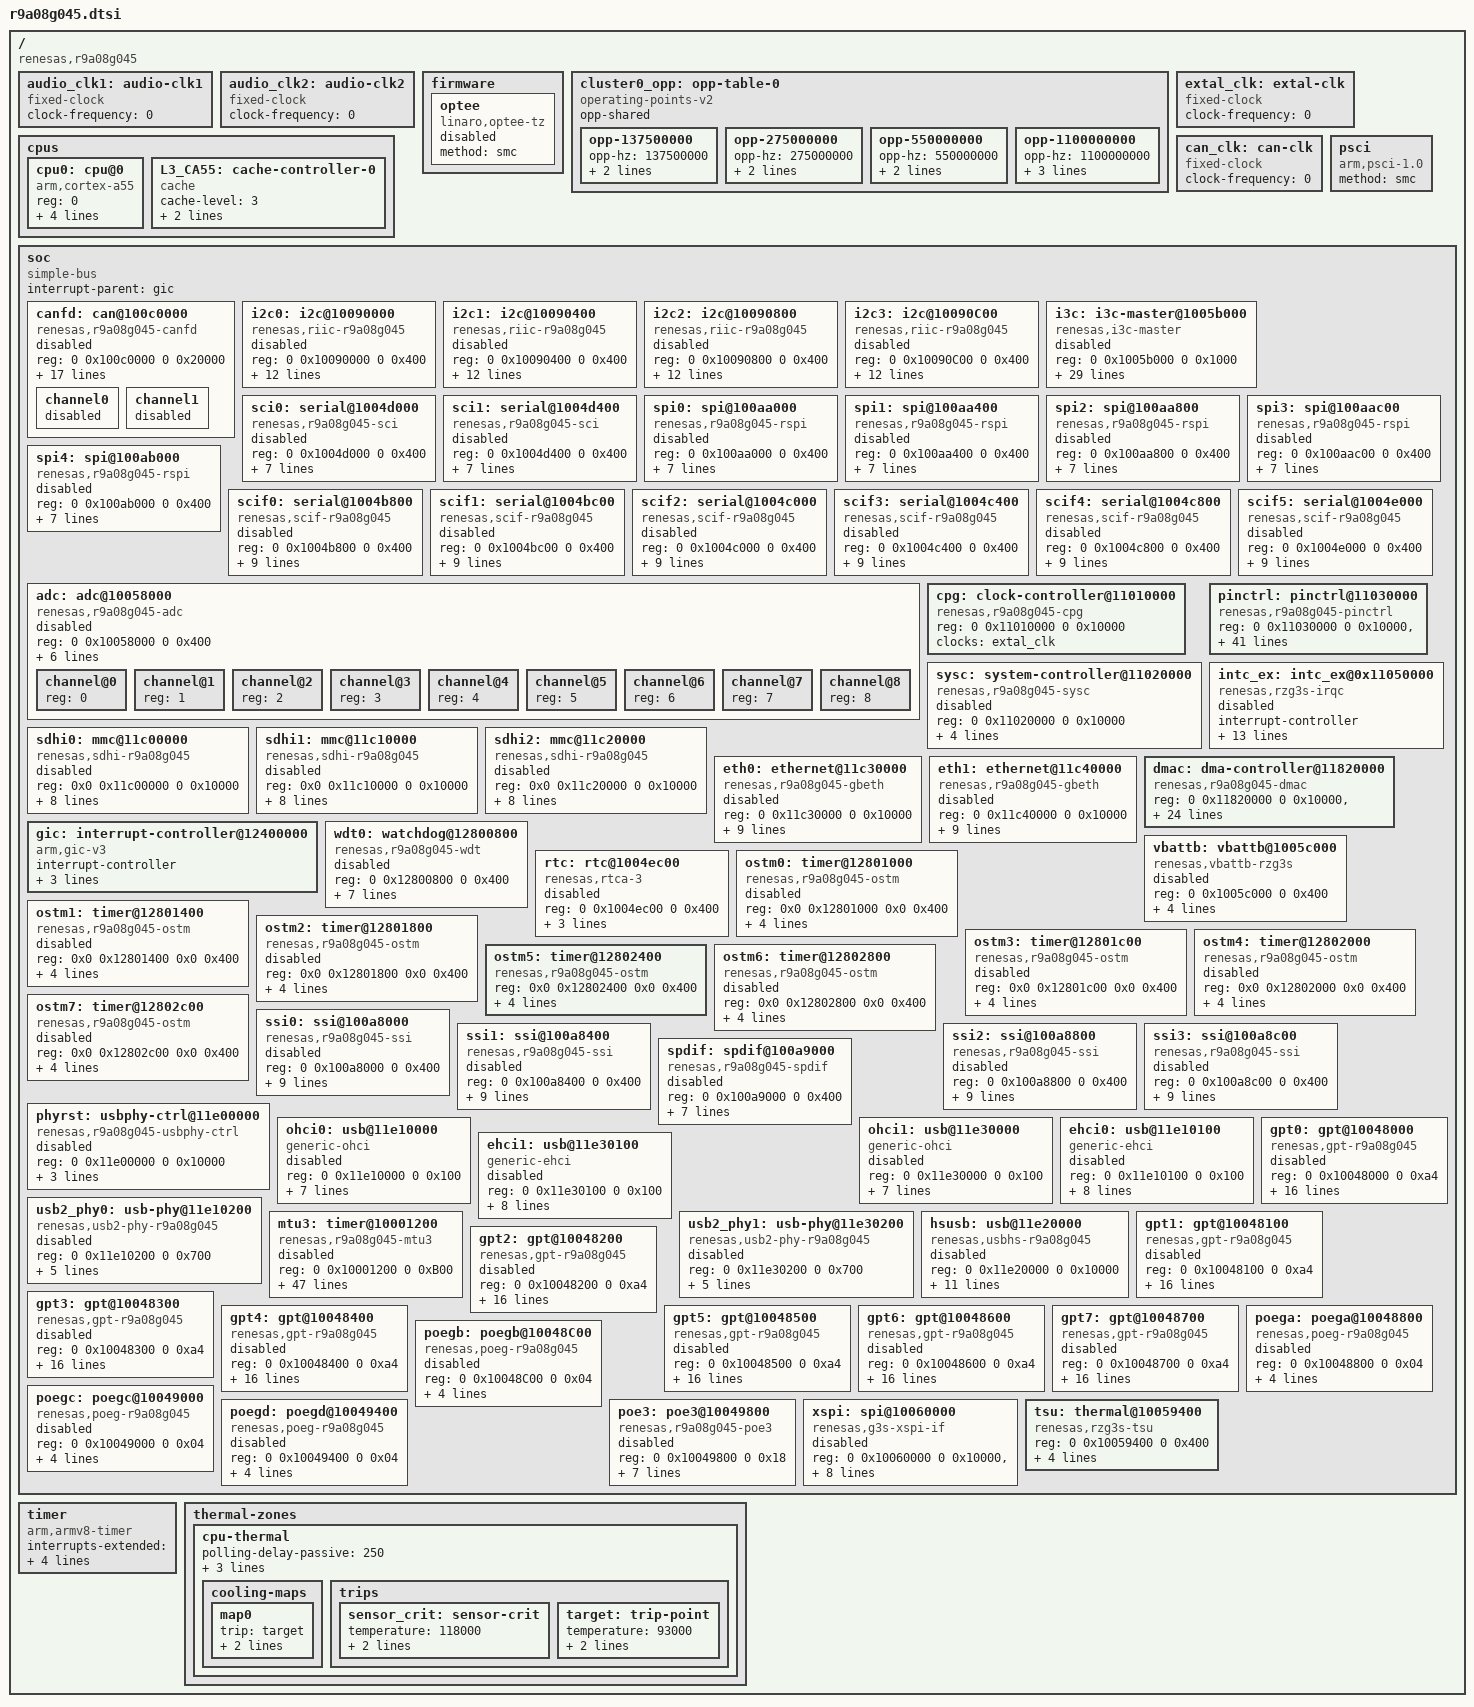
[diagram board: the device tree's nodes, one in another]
// SPDX-License-Identifier: (GPL-2.0-only OR BSD-2-Clause)
/*
 * Device Tree Source for the RZ/G3S SoC
 *
 * Copyright (C) 2023 Renesas Electronics Corp.
 */

#include <dt-bindings/interrupt-controller/arm-gic.h>
#include <dt-bindings/clock/r9a08g045-cpg.h>

/ {
	compatible = "renesas,r9a08g045";
	#address-cells = <2>;
	#size-cells = <2>;

	audio_clk1: audio-clk1 {
		compatible = "fixed-clock";
		#clock-cells = <0>;
		/* This value must be overridden by boards that provide it */
		clock-frequency = <0>;
	};

	audio_clk2: audio-clk2 {
		compatible = "fixed-clock";
		#clock-cells = <0>;
		/* This value must be overridden by boards that provide it */
		clock-frequency = <0>;
	};

	firmware {
		optee {
			compatible = "linaro,optee-tz";
			method = "smc";
			status = "disabled";
		};
	};

	cluster0_opp: opp-table-0 {
		compatible = "operating-points-v2";
		opp-shared;

		opp-137500000 {
			opp-hz = /bits/ 64 <137500000>;
			opp-microvolt = <1100000>;
			clock-latency-ns = <300000>;
		};
		opp-275000000 {
			opp-hz = /bits/ 64 <275000000>;
			opp-microvolt = <1100000>;
			clock-latency-ns = <300000>;
		};
		opp-550000000 {
			opp-hz = /bits/ 64 <550000000>;
			opp-microvolt = <1100000>;
			clock-latency-ns = <300000>;
		};
		opp-1100000000 {
			opp-hz = /bits/ 64 <1100000000>;
			opp-microvolt = <1100000>;
			clock-latency-ns = <300000>;
			opp-suspend;
		};
	};

	cpus {
		#address-cells = <1>;
		#size-cells = <0>;

		cpu0: cpu@0 {
			compatible = "arm,cortex-a55";
			reg = <0>;
			device_type = "cpu";
			#cooling-cells = <2>;
			next-level-cache = <&L3_CA55>;
			enable-method = "psci";
			clocks = <&cpg CPG_CORE R9A08G045_CLK_I>;
			operating-points-v2 = <&cluster0_opp>;
		};

		L3_CA55: cache-controller-0 {
			compatible = "cache";
			cache-level = <3>;
			cache-unified;
			cache-size = <0x40000>;
		};
	};

	extal_clk: extal-clk {
		compatible = "fixed-clock";
		#clock-cells = <0>;
		/* This value must be overridden by the board. */
		clock-frequency = <0>;
	};

	/* External CAN clock - to be overridden by boards that provide it */
	can_clk: can-clk {
		compatible = "fixed-clock";
		#clock-cells = <0>;
		 clock-frequency = <0>;
	};

	psci {
		compatible = "arm,psci-1.0", "arm,psci-0.2";
		method = "smc";
	};

	soc: soc {
		compatible = "simple-bus";
		interrupt-parent = <&gic>;
		#address-cells = <2>;
		#size-cells = <2>;
		ranges;

		canfd: can@100c0000 {
			compatible = "renesas,r9a08g045-canfd", "renesas,rzg3s-canfd";
			reg = <0 0x100c0000 0 0x20000>;
			interrupts = <GIC_SPI 373 IRQ_TYPE_LEVEL_HIGH>,
				     <GIC_SPI 374 IRQ_TYPE_LEVEL_HIGH>,
				     <GIC_SPI 375 IRQ_TYPE_LEVEL_HIGH>,
				     <GIC_SPI 376 IRQ_TYPE_LEVEL_HIGH>,
				     <GIC_SPI 377 IRQ_TYPE_LEVEL_HIGH>,
				     <GIC_SPI 378 IRQ_TYPE_LEVEL_HIGH>,
				     <GIC_SPI 379 IRQ_TYPE_LEVEL_HIGH>,
				     <GIC_SPI 380 IRQ_TYPE_LEVEL_HIGH>;
			interrupt-names = "g_err", "g_recc",
					  "ch0_rec", "ch1_rec", "ch0_err",
					  "ch1_err", "ch0_trx", "ch1_trx";
			clocks = <&cpg CPG_MOD R9A08G045_CANFD_CLK_RAM>,
				 <&cpg CPG_MOD R9A08G045_CANFD_PCLK>,
				 <&cpg CPG_CORE R9A08G045_CLK_CANFD>,
				 <&can_clk>;
			clock-names = "ram_clk", "fck", "canfd", "can_clk";
			assigned-clocks = <&cpg CPG_MOD R9A08G045_CANFD_PCLK>;
			assigned-clock-rates = <80000000>;
			resets = <&cpg R9A08G045_CANFD_RSTP_N>,
				 <&cpg R9A08G045_CANFD_RSTC_N>;
			reset-names = "rstp_n", "rstc_n";
			power-domains = <&cpg>;
			status = "disabled";

			channel0 {
				 status = "disabled";
			};
			channel1 {
				status = "disabled";
			};
		};

		i2c0: i2c@10090000 {
			#address-cells = <1>;
			#size-cells = <0>;
			compatible = "renesas,riic-r9a08g045";
			reg = <0 0x10090000 0 0x400>;
			interrupts = <GIC_SPI 257 IRQ_TYPE_LEVEL_HIGH>,
				     <GIC_SPI 263 IRQ_TYPE_EDGE_RISING>,
				     <GIC_SPI 264 IRQ_TYPE_EDGE_RISING>,
				     <GIC_SPI 259 IRQ_TYPE_LEVEL_HIGH>,
				     <GIC_SPI 260 IRQ_TYPE_LEVEL_HIGH>,
				     <GIC_SPI 258 IRQ_TYPE_LEVEL_HIGH>,
				     <GIC_SPI 261 IRQ_TYPE_LEVEL_HIGH>,
				     <GIC_SPI 262 IRQ_TYPE_LEVEL_HIGH>;
			interrupt-names = "tei", "ri", "ti", "spi", "sti",
					  "naki", "ali", "tmoi";
			clocks = <&cpg CPG_MOD R9A08G045_I2C0_PCLK>;
			clock-frequency = <100000>;
			resets = <&cpg R9A08G045_I2C0_MRST>;
			power-domains = <&cpg>;
			status = "disabled";
		};

		i2c1: i2c@10090400 {
			#address-cells = <1>;
			#size-cells = <0>;
			compatible = "renesas,riic-r9a08g045";
			reg = <0 0x10090400 0 0x400>;
			interrupts = <GIC_SPI 265 IRQ_TYPE_LEVEL_HIGH>,
				     <GIC_SPI 271 IRQ_TYPE_EDGE_RISING>,
				     <GIC_SPI 272 IRQ_TYPE_EDGE_RISING>,
				     <GIC_SPI 267 IRQ_TYPE_LEVEL_HIGH>,
				     <GIC_SPI 268 IRQ_TYPE_LEVEL_HIGH>,
				     <GIC_SPI 266 IRQ_TYPE_LEVEL_HIGH>,
				     <GIC_SPI 269 IRQ_TYPE_LEVEL_HIGH>,
				     <GIC_SPI 270 IRQ_TYPE_LEVEL_HIGH>;
			interrupt-names = "tei", "ri", "ti", "spi", "sti",
					  "naki", "ali", "tmoi";
			clocks = <&cpg CPG_MOD R9A08G045_I2C1_PCLK>;
			clock-frequency = <100000>;
			resets = <&cpg R9A08G045_I2C1_MRST>;
			power-domains = <&cpg>;
			status = "disabled";
		};

		i2c2: i2c@10090800 {
			#address-cells = <1>;
			#size-cells = <0>;
			compatible = "renesas,riic-r9a08g045";
			reg = <0 0x10090800 0 0x400>;
			interrupts = <GIC_SPI 273 IRQ_TYPE_LEVEL_HIGH>,
				     <GIC_SPI 279 IRQ_TYPE_EDGE_RISING>,
				     <GIC_SPI 280 IRQ_TYPE_EDGE_RISING>,
				     <GIC_SPI 275 IRQ_TYPE_LEVEL_HIGH>,
				     <GIC_SPI 276 IRQ_TYPE_LEVEL_HIGH>,
				     <GIC_SPI 274 IRQ_TYPE_LEVEL_HIGH>,
				     <GIC_SPI 277 IRQ_TYPE_LEVEL_HIGH>,
				     <GIC_SPI 278 IRQ_TYPE_LEVEL_HIGH>;
			interrupt-names = "tei", "ri", "ti", "spi", "sti",
					  "naki", "ali", "tmoi";
			clocks = <&cpg CPG_MOD R9A08G045_I2C2_PCLK>;
			clock-frequency = <100000>;
			resets = <&cpg R9A08G045_I2C2_MRST>;
			power-domains = <&cpg>;
			status = "disabled";
		};

		i2c3: i2c@10090C00 {
			#address-cells = <1>;
			#size-cells = <0>;
			compatible = "renesas,riic-r9a08g045";
			reg = <0 0x10090C00 0 0x400>;
			interrupts = <GIC_SPI 281 IRQ_TYPE_LEVEL_HIGH>,
				     <GIC_SPI 287 IRQ_TYPE_EDGE_RISING>,
				     <GIC_SPI 288 IRQ_TYPE_EDGE_RISING>,
				     <GIC_SPI 283 IRQ_TYPE_LEVEL_HIGH>,
				     <GIC_SPI 284 IRQ_TYPE_LEVEL_HIGH>,
				     <GIC_SPI 282 IRQ_TYPE_LEVEL_HIGH>,
				     <GIC_SPI 285 IRQ_TYPE_LEVEL_HIGH>,
				     <GIC_SPI 286 IRQ_TYPE_LEVEL_HIGH>;
			interrupt-names = "tei", "ri", "ti", "spi", "sti",
					  "naki", "ali", "tmoi";
			clocks = <&cpg CPG_MOD R9A08G045_I2C3_PCLK>;
			clock-frequency = <100000>;
			resets = <&cpg R9A08G045_I2C3_MRST>;
			power-domains = <&cpg>;
			status = "disabled";
		};

		i3c: i3c-master@1005b000 {
			compatible = "renesas,i3c-master";
			reg = <0 0x1005b000 0 0x1000>;
			clocks = <&cpg CPG_MOD R9A08G045_I3C_PCLK>,
				 <&cpg CPG_MOD R9A08G045_I3C_TCLK>;
			clock-names = "pclk", "tclk";
			interrupts = <GIC_SPI 289 IRQ_TYPE_LEVEL_HIGH>,
				     <GIC_SPI 290 IRQ_TYPE_LEVEL_HIGH>,
				     <GIC_SPI 291 IRQ_TYPE_LEVEL_HIGH>,
				     <GIC_SPI 292 IRQ_TYPE_LEVEL_HIGH>,
				     <GIC_SPI 293 IRQ_TYPE_LEVEL_HIGH>,
				     <GIC_SPI 294 IRQ_TYPE_EDGE_RISING>,
				     <GIC_SPI 295 IRQ_TYPE_EDGE_RISING>,
				     <GIC_SPI 296 IRQ_TYPE_EDGE_RISING>,
				     <GIC_SPI 297 IRQ_TYPE_EDGE_RISING>,
				     <GIC_SPI 298 IRQ_TYPE_EDGE_RISING>,
				     <GIC_SPI 299 IRQ_TYPE_EDGE_RISING>,
				     <GIC_SPI 300 IRQ_TYPE_EDGE_RISING>,
				     <GIC_SPI 301 IRQ_TYPE_EDGE_RISING>,
				     <GIC_SPI 302 IRQ_TYPE_EDGE_RISING>,
				     <GIC_SPI 303 IRQ_TYPE_EDGE_RISING>,
				     <GIC_SPI 304 IRQ_TYPE_LEVEL_HIGH>,
				     <GIC_SPI 305 IRQ_TYPE_LEVEL_HIGH>,
				     <GIC_SPI 306 IRQ_TYPE_LEVEL_HIGH>,
				     <GIC_SPI 307 IRQ_TYPE_LEVEL_HIGH>,
				     <GIC_SPI 308 IRQ_TYPE_LEVEL_HIGH>,
				     <GIC_SPI 309 IRQ_TYPE_LEVEL_HIGH>,
				     <GIC_SPI 310 IRQ_TYPE_LEVEL_HIGH>,
				     <GIC_SPI 311 IRQ_TYPE_LEVEL_HIGH>;
			interrupt-names = "ierr", "terr", "hterr", "habort", "abort",
					  "resp", "cmd", "ibi", "rx", "tx", "rcv",
					  "hresp", "hcmd", "hrx", "htx", "st", "sp",
					  "exit", "tend", "nack", "al", "tmo", "wu";
			resets = <&cpg R9A08G045_I3C_TRESETN>,
				 <&cpg R9A08G045_I3C_PRESETN>;
			reset-names = "tresetn", "presetn";
			#address-cells = <3>;
			#size-cells = <0>;
			i2c-scl-hz = <1000000>;
			i3c-scl-hz = <12500000>;
			status = "disabled";
		};

		sci0: serial@1004d000 {
			compatible = "renesas,r9a08g045-sci", "renesas,sci";
			reg = <0 0x1004d000 0 0x400>;
			interrupts = <GIC_SPI 350 IRQ_TYPE_LEVEL_HIGH>,
				     <GIC_SPI 351 IRQ_TYPE_EDGE_RISING>,
				     <GIC_SPI 352 IRQ_TYPE_EDGE_RISING>,
				     <GIC_SPI 353 IRQ_TYPE_LEVEL_HIGH>;
			interrupt-names = "eri", "rxi", "txi", "tei";
			clocks = <&cpg CPG_MOD R9A08G045_SCI0_CLKP>;
			clock-names = "fck";
			power-domains = <&cpg>;
			resets = <&cpg R9A08G045_SCI0_RST>;
			status = "disabled";
		};

		sci1: serial@1004d400 {
			compatible = "renesas,r9a08g045-sci", "renesas,sci";
			reg = <0 0x1004d400 0 0x400>;
			interrupts = <GIC_SPI 354 IRQ_TYPE_LEVEL_HIGH>,
				     <GIC_SPI 355 IRQ_TYPE_EDGE_RISING>,
				     <GIC_SPI 356 IRQ_TYPE_EDGE_RISING>,
				     <GIC_SPI 357 IRQ_TYPE_LEVEL_HIGH>;
			interrupt-names = "eri", "rxi", "txi", "tei";
			clocks = <&cpg CPG_MOD R9A08G045_SCI1_CLKP>;
			clock-names = "fck";
			power-domains = <&cpg>;
			resets = <&cpg R9A08G045_SCI1_RST>;
			status = "disabled";
		};

		spi0: spi@100aa000 {
			compatible = "renesas,r9a08g045-rspi", "renesas,rspi-rz";
			reg = <0 0x100aa000 0 0x400>;
			interrupts = <GIC_SPI 358 IRQ_TYPE_LEVEL_HIGH>,
				     <GIC_SPI 359 IRQ_TYPE_LEVEL_HIGH>,
				     <GIC_SPI 360 IRQ_TYPE_LEVEL_HIGH>;
			interrupt-names = "error", "rx", "tx";
			clocks = <&cpg CPG_MOD R9A08G045_RSPI0_CLKB>;
			resets = <&cpg R9A08G045_RSPI0_RST>;
			power-domains = <&cpg>;
			num-cs = <1>;
			#address-cells = <1>;
			#size-cells = <0>;
			status = "disabled";
		};

		spi1: spi@100aa400 {
			compatible = "renesas,r9a08g045-rspi", "renesas,rspi-rz";
			reg = <0 0x100aa400 0 0x400>;
			interrupts = <GIC_SPI 361 IRQ_TYPE_LEVEL_HIGH>,
				     <GIC_SPI 362 IRQ_TYPE_LEVEL_HIGH>,
				     <GIC_SPI 363 IRQ_TYPE_LEVEL_HIGH>;
			interrupt-names = "error", "rx", "tx";
			clocks = <&cpg CPG_MOD R9A08G045_RSPI1_CLKB>;
			resets = <&cpg R9A08G045_RSPI1_RST>;
			power-domains = <&cpg>;
			num-cs = <1>;
			#address-cells = <1>;
			#size-cells = <0>;
			status = "disabled";
		};

		spi2: spi@100aa800 {
			compatible = "renesas,r9a08g045-rspi", "renesas,rspi-rz";
			reg = <0 0x100aa800 0 0x400>;
			interrupts = <GIC_SPI 364 IRQ_TYPE_LEVEL_HIGH>,
				     <GIC_SPI 365 IRQ_TYPE_LEVEL_HIGH>,
				     <GIC_SPI 366 IRQ_TYPE_LEVEL_HIGH>;
			interrupt-names = "error", "rx", "tx";
			clocks = <&cpg CPG_MOD R9A08G045_RSPI2_CLKB>;
			resets = <&cpg R9A08G045_RSPI2_RST>;
			power-domains = <&cpg>;
			num-cs = <1>;
			#address-cells = <1>;
			#size-cells = <0>;
			status = "disabled";
		};

		spi3: spi@100aac00 {
			compatible = "renesas,r9a08g045-rspi", "renesas,rspi-rz";
			reg = <0 0x100aac00 0 0x400>;
			interrupts = <GIC_SPI 367 IRQ_TYPE_LEVEL_HIGH>,
				     <GIC_SPI 368 IRQ_TYPE_LEVEL_HIGH>,
				     <GIC_SPI 369 IRQ_TYPE_LEVEL_HIGH>;
			interrupt-names = "error", "rx", "tx";
			clocks = <&cpg CPG_MOD R9A08G045_RSPI3_CLKB>;
			resets = <&cpg R9A08G045_RSPI3_RST>;
			power-domains = <&cpg>;
			num-cs = <1>;
			#address-cells = <1>;
			#size-cells = <0>;
			status = "disabled";
		};

		spi4: spi@100ab000 {
			compatible = "renesas,r9a08g045-rspi", "renesas,rspi-rz";
			reg = <0 0x100ab000 0 0x400>;
			interrupts = <GIC_SPI 370 IRQ_TYPE_LEVEL_HIGH>,
				     <GIC_SPI 371 IRQ_TYPE_LEVEL_HIGH>,
				     <GIC_SPI 372 IRQ_TYPE_LEVEL_HIGH>;
			interrupt-names = "error", "rx", "tx";
			clocks = <&cpg CPG_MOD R9A08G045_RSPI4_CLKB>;
			resets = <&cpg R9A08G045_RSPI4_RST>;
			power-domains = <&cpg>;
			num-cs = <1>;
			#address-cells = <1>;
			#size-cells = <0>;
			status = "disabled";
		};

		scif0: serial@1004b800 {
			compatible = "renesas,scif-r9a08g045", "renesas,scif-r9a07g044";
			reg = <0 0x1004b800 0 0x400>;
			interrupts = <GIC_SPI 320 IRQ_TYPE_LEVEL_HIGH>,
				     <GIC_SPI 322 IRQ_TYPE_LEVEL_HIGH>,
				     <GIC_SPI 323 IRQ_TYPE_LEVEL_HIGH>,
				     <GIC_SPI 321 IRQ_TYPE_LEVEL_HIGH>,
				     <GIC_SPI 324 IRQ_TYPE_LEVEL_HIGH>,
				     <GIC_SPI 324 IRQ_TYPE_LEVEL_HIGH>;
			interrupt-names = "eri", "rxi", "txi",
					  "bri", "dri", "tei";
			clocks = <&cpg CPG_MOD R9A08G045_SCIF0_CLK_PCK>;
			clock-names = "fck";
			power-domains = <&cpg>;
			resets = <&cpg R9A08G045_SCIF0_RST_SYSTEM_N>;
			status = "disabled";
		};

		scif1: serial@1004bc00 {
			compatible = "renesas,scif-r9a08g045";
			reg = <0 0x1004bc00 0 0x400>;
			interrupts = <GIC_SPI 325 IRQ_TYPE_LEVEL_HIGH>,
				     <GIC_SPI 327 IRQ_TYPE_LEVEL_HIGH>,
				     <GIC_SPI 328 IRQ_TYPE_LEVEL_HIGH>,
				     <GIC_SPI 326 IRQ_TYPE_LEVEL_HIGH>,
				     <GIC_SPI 329 IRQ_TYPE_LEVEL_HIGH>,
				     <GIC_SPI 329 IRQ_TYPE_LEVEL_HIGH>;
			interrupt-names = "eri", "rxi", "txi",
					  "bri", "dri", "tei";
			clocks = <&cpg CPG_MOD R9A08G045_SCIF1_CLK_PCK>;
			clock-names = "fck";
			power-domains = <&cpg>;
			resets = <&cpg R9A08G045_SCIF1_RST_SYSTEM_N>;
			status = "disabled";
		};

		scif2: serial@1004c000 {
			compatible = "renesas,scif-r9a08g045";
			reg = <0 0x1004c000 0 0x400>;
			interrupts = <GIC_SPI 330 IRQ_TYPE_LEVEL_HIGH>,
				     <GIC_SPI 332 IRQ_TYPE_LEVEL_HIGH>,
				     <GIC_SPI 333 IRQ_TYPE_LEVEL_HIGH>,
				     <GIC_SPI 331 IRQ_TYPE_LEVEL_HIGH>,
				     <GIC_SPI 334 IRQ_TYPE_LEVEL_HIGH>,
				     <GIC_SPI 334 IRQ_TYPE_LEVEL_HIGH>;
			interrupt-names = "eri", "rxi", "txi",
					  "bri", "dri", "tei";
			clocks = <&cpg CPG_MOD R9A08G045_SCIF2_CLK_PCK>;
			clock-names = "fck";
			power-domains = <&cpg>;
			resets = <&cpg R9A08G045_SCIF2_RST_SYSTEM_N>;
			status = "disabled";
		};

		scif3: serial@1004c400 {
			compatible = "renesas,scif-r9a08g045";
			reg = <0 0x1004c400 0 0x400>;
			interrupts = <GIC_SPI 335 IRQ_TYPE_LEVEL_HIGH>,
				     <GIC_SPI 337 IRQ_TYPE_LEVEL_HIGH>,
				     <GIC_SPI 338 IRQ_TYPE_LEVEL_HIGH>,
				     <GIC_SPI 336 IRQ_TYPE_LEVEL_HIGH>,
				     <GIC_SPI 339 IRQ_TYPE_LEVEL_HIGH>,
				     <GIC_SPI 339 IRQ_TYPE_LEVEL_HIGH>;
			interrupt-names = "eri", "rxi", "txi",
					  "bri", "dri", "tei";
			clocks = <&cpg CPG_MOD R9A08G045_SCIF3_CLK_PCK>;
			clock-names = "fck";
			power-domains = <&cpg>;
			resets = <&cpg R9A08G045_SCIF3_RST_SYSTEM_N>;
			status = "disabled";
		};

		scif4: serial@1004c800 {
			compatible = "renesas,scif-r9a08g045";
			reg = <0 0x1004c800 0 0x400>;
			interrupts = <GIC_SPI 340 IRQ_TYPE_LEVEL_HIGH>,
				     <GIC_SPI 342 IRQ_TYPE_LEVEL_HIGH>,
				     <GIC_SPI 343 IRQ_TYPE_LEVEL_HIGH>,
				     <GIC_SPI 341 IRQ_TYPE_LEVEL_HIGH>,
				     <GIC_SPI 344 IRQ_TYPE_LEVEL_HIGH>,
				     <GIC_SPI 344 IRQ_TYPE_LEVEL_HIGH>;
			interrupt-names = "eri", "rxi", "txi",
					  "bri", "dri", "tei";
			clocks = <&cpg CPG_MOD R9A08G045_SCIF4_CLK_PCK>;
			clock-names = "fck";
			power-domains = <&cpg>;
			resets = <&cpg R9A08G045_SCIF4_RST_SYSTEM_N>;
			status = "disabled";
		};

		scif5: serial@1004e000 {
			compatible = "renesas,scif-r9a08g045";
			reg = <0 0x1004e000 0 0x400>;
			interrupts = <GIC_SPI 345 IRQ_TYPE_LEVEL_HIGH>,
				     <GIC_SPI 347 IRQ_TYPE_LEVEL_HIGH>,
				     <GIC_SPI 348 IRQ_TYPE_LEVEL_HIGH>,
				     <GIC_SPI 346 IRQ_TYPE_LEVEL_HIGH>,
				     <GIC_SPI 349 IRQ_TYPE_LEVEL_HIGH>,
				     <GIC_SPI 349 IRQ_TYPE_LEVEL_HIGH>;
			interrupt-names = "eri", "rxi", "txi",
					  "bri", "dri", "tei";
			clocks = <&cpg CPG_MOD R9A08G045_SCIF5_CLK_PCK>;
			clock-names = "fck";
			power-domains = <&cpg>;
			resets = <&cpg R9A08G045_SCIF5_RST_SYSTEM_N>;
			status = "disabled";
		};

		adc: adc@10058000 {
			compatible = "renesas,r9a08g045-adc",
				     "renesas,rzg3s-adc";
			reg = <0 0x10058000 0 0x400>;
			interrupts = <GIC_SPI 312 IRQ_TYPE_EDGE_RISING>;
			clocks = <&cpg CPG_MOD R9A08G045_ADC_ADCLK>,
				 <&cpg CPG_MOD R9A08G045_ADC_PCLK>;
			clock-names = "adclk", "pclk";
			resets = <&cpg R9A08G045_ADC_PRESETN>,
				 <&cpg R9A08G045_ADC_ADRST_N>;
			reset-names = "presetn", "adrst-n";
			power-domains = <&cpg>;
			status = "disabled";

			#address-cells = <1>;
			#size-cells = <0>;

			channel@0 {
				reg = <0>;
			};
			channel@1 {
				reg = <1>;
			};
			channel@2 {
				reg = <2>;
			};
			channel@3 {
				reg = <3>;
			};
			channel@4 {
				reg = <4>;
			};
			channel@5 {
				reg = <5>;
			};
			channel@6 {
				reg = <6>;
			};
			channel@7 {
				reg = <7>;
			};
			channel@8 {
				reg = <8>;
			};
		};

		cpg: clock-controller@11010000 {
			compatible = "renesas,r9a08g045-cpg";
			reg = <0 0x11010000 0 0x10000>;
			clocks = <&extal_clk>;
			clock-names = "extal";
			#clock-cells = <2>;
			#reset-cells = <1>;
			#power-domain-cells = <0>;
		};

		sysc: system-controller@11020000 {
			compatible = "renesas,r9a08g045-sysc";
			reg = <0 0x11020000 0 0x10000>;
			interrupts = <GIC_SPI 39 IRQ_TYPE_LEVEL_HIGH>,
				     <GIC_SPI 40 IRQ_TYPE_LEVEL_HIGH>,
				     <GIC_SPI 41 IRQ_TYPE_LEVEL_HIGH>,
				     <GIC_SPI 42 IRQ_TYPE_LEVEL_HIGH>;
			interrupt-names = "lpm_int", "ca55stbydone_int",
					  "cm33stbyr_int", "ca55_deny";
			status = "disabled";
		};

		pinctrl: pinctrl@11030000 {
			compatible = "renesas,r9a08g045-pinctrl";
			reg = <0 0x11030000 0 0x10000>,<0 0x11050020 0 0x30>;
			gpio-controller;
			#gpio-cells = <2>;
			interrupt-controller;
			#interrupt-cells = <2>;
			gpio-ranges = <&pinctrl 0 0 152>;
			clocks = <&cpg CPG_MOD R9A08G045_GPIO_HCLK>;
			power-domains = <&cpg>;
			resets = <&cpg R9A08G045_GPIO_RSTN>,
				 <&cpg R9A08G045_GPIO_PORT_RESETN>,
				 <&cpg R9A08G045_GPIO_SPARE_RESETN>;
			interrupts =  <GIC_SPI 429 IRQ_TYPE_LEVEL_HIGH>,
				      <GIC_SPI 430 IRQ_TYPE_LEVEL_HIGH>,
				      <GIC_SPI 431 IRQ_TYPE_LEVEL_HIGH>,
				      <GIC_SPI 432 IRQ_TYPE_LEVEL_HIGH>,
				      <GIC_SPI 433 IRQ_TYPE_LEVEL_HIGH>,
				      <GIC_SPI 434 IRQ_TYPE_LEVEL_HIGH>,
				      <GIC_SPI 435 IRQ_TYPE_LEVEL_HIGH>,
				      <GIC_SPI 436 IRQ_TYPE_LEVEL_HIGH>,
				      <GIC_SPI 437 IRQ_TYPE_LEVEL_HIGH>,
				      <GIC_SPI 438 IRQ_TYPE_LEVEL_HIGH>,
				      <GIC_SPI 439 IRQ_TYPE_LEVEL_HIGH>,
				      <GIC_SPI 440 IRQ_TYPE_LEVEL_HIGH>,
				      <GIC_SPI 441 IRQ_TYPE_LEVEL_HIGH>,
				      <GIC_SPI 442 IRQ_TYPE_LEVEL_HIGH>,
				      <GIC_SPI 443 IRQ_TYPE_LEVEL_HIGH>,
				      <GIC_SPI 444 IRQ_TYPE_LEVEL_HIGH>,
				      <GIC_SPI 445 IRQ_TYPE_LEVEL_HIGH>,
				      <GIC_SPI 446 IRQ_TYPE_LEVEL_HIGH>,
				      <GIC_SPI 447 IRQ_TYPE_LEVEL_HIGH>,
				      <GIC_SPI 448 IRQ_TYPE_LEVEL_HIGH>,
				      <GIC_SPI 449 IRQ_TYPE_LEVEL_HIGH>,
				      <GIC_SPI 450 IRQ_TYPE_LEVEL_HIGH>,
				      <GIC_SPI 451 IRQ_TYPE_LEVEL_HIGH>,
				      <GIC_SPI 452 IRQ_TYPE_LEVEL_HIGH>,
				      <GIC_SPI 453 IRQ_TYPE_LEVEL_HIGH>,
				      <GIC_SPI 454 IRQ_TYPE_LEVEL_HIGH>,
				      <GIC_SPI 455 IRQ_TYPE_LEVEL_HIGH>,
				      <GIC_SPI 456 IRQ_TYPE_LEVEL_HIGH>,
				      <GIC_SPI 457 IRQ_TYPE_LEVEL_HIGH>,
				      <GIC_SPI 458 IRQ_TYPE_LEVEL_HIGH>,
				      <GIC_SPI 459 IRQ_TYPE_LEVEL_HIGH>,
				      <GIC_SPI 460 IRQ_TYPE_LEVEL_HIGH>;

		};

		intc_ex: intc_ex@0x11050000 {
			compatible = "renesas,rzg3s-irqc";
			#interrupt-cells = <2>;
			interrupt-controller;
			reg = <0x0 0x11050000 0 0x10000>;
			interrupts = <GIC_SPI 1 IRQ_TYPE_LEVEL_HIGH>,
				<GIC_SPI 2 IRQ_TYPE_LEVEL_HIGH>,
				<GIC_SPI 3 IRQ_TYPE_LEVEL_HIGH>,
				<GIC_SPI 4 IRQ_TYPE_LEVEL_HIGH>,
				<GIC_SPI 5 IRQ_TYPE_LEVEL_HIGH>,
				<GIC_SPI 6 IRQ_TYPE_LEVEL_HIGH>,
				<GIC_SPI 7 IRQ_TYPE_LEVEL_HIGH>,
				<GIC_SPI 8 IRQ_TYPE_LEVEL_HIGH>,
				<GIC_SPI 0 IRQ_TYPE_LEVEL_HIGH>;
			interrupt-names = "irq0", "irq1", "irq2", "irq3",
				"irq4", "irq5", "irq6", "irq7", "nmi";
			clocks = <&cpg CPG_MOD R9A08G045_IA55_CLK>;
			resets = <&cpg R9A08G045_IA55_RESETN>;
			power-domains = <&cpg>;
			status = "disabled";
		};

		sdhi0: mmc@11c00000  {
			compatible = "renesas,sdhi-r9a08g045", "renesas,rcar-gen3-sdhi";
			reg = <0x0 0x11c00000 0 0x10000>;
			interrupts = <GIC_SPI 88 IRQ_TYPE_LEVEL_HIGH>,
				     <GIC_SPI 89 IRQ_TYPE_LEVEL_HIGH>;
			clocks = <&cpg CPG_MOD R9A08G045_SDHI0_IMCLK>,
				 <&cpg CPG_MOD R9A08G045_SDHI0_CLK_HS>,
				 <&cpg CPG_MOD R9A08G045_SDHI0_IMCLK2>,
				 <&cpg CPG_MOD R9A08G045_SDHI0_ACLK>;
			clock-names = "core", "clkh", "cd", "aclk";
			resets = <&cpg R9A08G045_SDHI0_IXRST>;
			power-domains = <&cpg>;
			status = "disabled";
		};

		sdhi1: mmc@11c10000 {
			compatible = "renesas,sdhi-r9a08g045", "renesas,rcar-gen3-sdhi";
			reg = <0x0 0x11c10000 0 0x10000>;
			interrupts = <GIC_SPI 90 IRQ_TYPE_LEVEL_HIGH>,
				     <GIC_SPI 91 IRQ_TYPE_LEVEL_HIGH>;
			clocks = <&cpg CPG_MOD R9A08G045_SDHI1_IMCLK>,
				 <&cpg CPG_MOD R9A08G045_SDHI1_CLK_HS>,
				 <&cpg CPG_MOD R9A08G045_SDHI1_IMCLK2>,
				 <&cpg CPG_MOD R9A08G045_SDHI1_ACLK>;
			clock-names = "core", "clkh", "cd", "aclk";
			resets = <&cpg R9A08G045_SDHI1_IXRST>;
			power-domains = <&cpg>;
			status = "disabled";
		};

		sdhi2: mmc@11c20000 {
			compatible = "renesas,sdhi-r9a08g045", "renesas,rcar-gen3-sdhi";
			reg = <0x0 0x11c20000 0 0x10000>;
			interrupts = <GIC_SPI 92 IRQ_TYPE_LEVEL_HIGH>,
				     <GIC_SPI 93 IRQ_TYPE_LEVEL_HIGH>;
			clocks = <&cpg CPG_MOD R9A08G045_SDHI2_IMCLK>,
				 <&cpg CPG_MOD R9A08G045_SDHI2_CLK_HS>,
				 <&cpg CPG_MOD R9A08G045_SDHI2_IMCLK2>,
				 <&cpg CPG_MOD R9A08G045_SDHI2_ACLK>;
			clock-names = "core", "clkh", "cd", "aclk";
			resets = <&cpg R9A08G045_SDHI2_IXRST>;
			power-domains = <&cpg>;
			status = "disabled";
		};

		eth0: ethernet@11c30000 {
			compatible = "renesas,r9a08g045-gbeth", "renesas,rzg2l-gbeth";
			reg = <0 0x11c30000 0 0x10000>;
			interrupts = <GIC_SPI 68 IRQ_TYPE_LEVEL_HIGH>,
				     <GIC_SPI 69 IRQ_TYPE_LEVEL_HIGH>,
				     <GIC_SPI 70 IRQ_TYPE_LEVEL_HIGH>;
			interrupt-names = "mux", "fil", "arp_ns";
			phy-mode = "rgmii";
			clocks = <&cpg CPG_MOD R9A08G045_ETH0_CLK_AXI>,
				 <&cpg CPG_MOD R9A08G045_ETH0_CLK_CHI>,
				 <&cpg CPG_MOD R9A08G045_ETH0_REFCLK>;
			clock-names = "axi", "chi", "refclk";
			resets = <&cpg R9A08G045_ETH0_RST_HW_N>;
			power-domains = <&cpg>;
			#address-cells = <1>;
			#size-cells = <0>;
			status = "disabled";
		};

		eth1: ethernet@11c40000 {
			compatible = "renesas,r9a08g045-gbeth", "renesas,rzg2l-gbeth";
			reg = <0 0x11c40000 0 0x10000>;
			interrupts = <GIC_SPI 71 IRQ_TYPE_LEVEL_HIGH>,
				     <GIC_SPI 72 IRQ_TYPE_LEVEL_HIGH>,
				     <GIC_SPI 73 IRQ_TYPE_LEVEL_HIGH>;
			interrupt-names = "mux", "fil", "arp_ns";
			phy-mode = "rgmii";
			clocks = <&cpg CPG_MOD R9A08G045_ETH1_CLK_AXI>,
				 <&cpg CPG_MOD R9A08G045_ETH1_CLK_CHI>,
				 <&cpg CPG_MOD R9A08G045_ETH1_REFCLK>;
			clock-names = "axi", "chi", "refclk";
			resets = <&cpg R9A08G045_ETH1_RST_HW_N>;
			power-domains = <&cpg>;
			#address-cells = <1>;
			#size-cells = <0>;
			status = "disabled";
		};

		dmac: dma-controller@11820000 {
			compatible = "renesas,r9a08g045-dmac",
				     "renesas,rz-dmac";
			reg = <0 0x11820000 0 0x10000>,
			      <0 0x11830000 0 0x10000>;
			interrupts = <GIC_SPI 111 IRQ_TYPE_EDGE_RISING>,
				     <GIC_SPI 112 IRQ_TYPE_EDGE_RISING>,
				     <GIC_SPI 113 IRQ_TYPE_EDGE_RISING>,
				     <GIC_SPI 114 IRQ_TYPE_EDGE_RISING>,
				     <GIC_SPI 115 IRQ_TYPE_EDGE_RISING>,
				     <GIC_SPI 116 IRQ_TYPE_EDGE_RISING>,
				     <GIC_SPI 117 IRQ_TYPE_EDGE_RISING>,
				     <GIC_SPI 118 IRQ_TYPE_EDGE_RISING>,
				     <GIC_SPI 119 IRQ_TYPE_EDGE_RISING>,
				     <GIC_SPI 120 IRQ_TYPE_EDGE_RISING>,
				     <GIC_SPI 121 IRQ_TYPE_EDGE_RISING>,
				     <GIC_SPI 122 IRQ_TYPE_EDGE_RISING>,
				     <GIC_SPI 123 IRQ_TYPE_EDGE_RISING>,
				     <GIC_SPI 124 IRQ_TYPE_EDGE_RISING>,
				     <GIC_SPI 125 IRQ_TYPE_EDGE_RISING>,
				     <GIC_SPI 126 IRQ_TYPE_EDGE_RISING>,
				     <GIC_SPI 127 IRQ_TYPE_EDGE_RISING>;
			interrupt-names = "error",
					  "ch0", "ch1", "ch2", "ch3",
					  "ch4", "ch5", "ch6", "ch7",
					  "ch8", "ch9", "ch10", "ch11",
					  "ch12", "ch13", "ch14", "ch15";
			clocks = <&cpg CPG_MOD R9A08G045_DMAC_ACLK>,
				 <&cpg CPG_MOD R9A08G045_DMAC_PCLK>;
			power-domains = <&cpg>;
			resets = <&cpg R9A08G045_DMAC_ARESETN>,
				 <&cpg R9A08G045_DMAC_RST_ASYNC>;
			#dma-cells = <1>;
			dma-channels = <16>;
		};

		gic: interrupt-controller@12400000 {
			compatible = "arm,gic-v3";
			#interrupt-cells = <3>;
			#address-cells = <0>;
			interrupt-controller;
			reg = <0x0 0x12400000 0 0x40000>,
			      <0x0 0x12440000 0 0x60000>;
			interrupts = <GIC_PPI 9 IRQ_TYPE_LEVEL_LOW>;
		};

		wdt0: watchdog@12800800 {
			compatible = "renesas,r9a08g045-wdt",
				     "renesas,rzg2l-wdt";
			reg = <0 0x12800800 0 0x400>;
			clocks = <&cpg CPG_MOD R9A08G045_WDT0_PCLK>,
				 <&cpg CPG_MOD R9A08G045_WDT0_CLK>;
			clock-names = "pclk", "oscclk";
			interrupts = <GIC_SPI 53 IRQ_TYPE_LEVEL_HIGH>,
				     <GIC_SPI 52 IRQ_TYPE_LEVEL_HIGH>;
			interrupt-names = "wdt", "perrout";
			resets = <&cpg R9A08G045_WDT0_PRESETN>;
			power-domains = <&cpg>;
			channel,id = <0>;
			status = "disabled";
		};

		vbattb: vbattb@1005c000 {
			compatible = "renesas,vbattb-rzg3s";
			reg = <0 0x1005c000 0 0x400>;
			clocks = <&cpg CPG_MOD R9A08G045_VBAT_BCLK>;
			clock-names = "bclk";
			interrupts = <GIC_SPI 43 IRQ_TYPE_LEVEL_HIGH>;
			interrupt-names = "tampdi";
			resets = <&cpg R9A08G045_VBAT_BRESETN>;
			power-domains = <&cpg>;
			status = "disabled";
		};

		rtc: rtc@1004ec00 {
			compatible = "renesas,rtca-3";
			reg = <0 0x1004ec00 0 0x400>;
			interrupts = <GIC_SPI 316 IRQ_TYPE_LEVEL_HIGH>,
				     <GIC_SPI 317 IRQ_TYPE_LEVEL_HIGH>,
				     <GIC_SPI 315 IRQ_TYPE_LEVEL_HIGH>;
			interrupt-names = "period", "carry", "alarm";
			status = "disabled";
		};

		ostm0: timer@12801000 {
			compatible = "renesas,r9a08g045-ostm",
				     "renesas,ostm";
			reg = <0x0 0x12801000 0x0 0x400>;
			interrupts = <GIC_SPI 44 IRQ_TYPE_EDGE_RISING>;
			clocks = <&cpg CPG_MOD R9A08G045_OSTM0_PCLK>;
			resets = <&cpg R9A08G045_OSTM0_PRESETZ>;
			power-domains = <&cpg>;
			status = "disabled";
		};

		ostm1: timer@12801400 {
			compatible = "renesas,r9a08g045-ostm",
				     "renesas,ostm";
			reg = <0x0 0x12801400 0x0 0x400>;
			interrupts = <GIC_SPI 45 IRQ_TYPE_EDGE_RISING>;
			clocks = <&cpg CPG_MOD R9A08G045_OSTM1_PCLK>;
			resets = <&cpg R9A08G045_OSTM1_PRESETZ>;
			power-domains = <&cpg>;
			status = "disabled";
		};

		ostm2: timer@12801800 {
			compatible = "renesas,r9a08g045-ostm",
				     "renesas,ostm";
			reg = <0x0 0x12801800 0x0 0x400>;
			interrupts = <GIC_SPI 46 IRQ_TYPE_EDGE_RISING>;
			clocks = <&cpg CPG_MOD R9A08G045_OSTM2_PCLK>;
			resets = <&cpg R9A08G045_OSTM2_PRESETZ>;
			power-domains = <&cpg>;
			status = "disabled";
		};

		ostm3: timer@12801c00 {
			compatible = "renesas,r9a08g045-ostm",
				     "renesas,ostm";
			reg = <0x0 0x12801c00 0x0 0x400>;
			interrupts = <GIC_SPI 47 IRQ_TYPE_EDGE_RISING>;
			clocks = <&cpg CPG_MOD R9A08G045_OSTM3_PCLK>;
			resets = <&cpg R9A08G045_OSTM3_PRESETZ>;
			power-domains = <&cpg>;
			status = "disabled";
		};

		ostm4: timer@12802000 {
			compatible = "renesas,r9a08g045-ostm",
				     "renesas,ostm";
			reg = <0x0 0x12802000 0x0 0x400>;
			interrupts = <GIC_SPI 48 IRQ_TYPE_EDGE_RISING>;
			clocks = <&cpg CPG_MOD R9A08G045_OSTM4_PCLK>;
			resets = <&cpg R9A08G045_OSTM4_PRESETZ>;
			power-domains = <&cpg>;
			status = "disabled";
		};

		ostm5: timer@12802400 {
			compatible = "renesas,r9a08g045-ostm",
				     "renesas,ostm";
			reg = <0x0 0x12802400 0x0 0x400>;
			interrupts = <GIC_SPI 49 IRQ_TYPE_EDGE_RISING>;
			clocks = <&cpg CPG_MOD R9A08G045_OSTM5_PCLK>;
			resets = <&cpg R9A08G045_OSTM5_PRESETZ>;
			power-domains = <&cpg>;
		};

		ostm6: timer@12802800 {
			compatible = "renesas,r9a08g045-ostm",
				     "renesas,ostm";
			reg = <0x0 0x12802800 0x0 0x400>;
			interrupts = <GIC_SPI 50 IRQ_TYPE_EDGE_RISING>;
			clocks = <&cpg CPG_MOD R9A08G045_OSTM6_PCLK>;
			resets = <&cpg R9A08G045_OSTM6_PRESETZ>;
			power-domains = <&cpg>;
			status = "disabled";
		};

		ostm7: timer@12802c00 {
			compatible = "renesas,r9a08g045-ostm",
				     "renesas,ostm";
			reg = <0x0 0x12802c00 0x0 0x400>;
			interrupts = <GIC_SPI 51 IRQ_TYPE_EDGE_RISING>;
			clocks = <&cpg CPG_MOD R9A08G045_OSTM7_PCLK>;
			resets = <&cpg R9A08G045_OSTM7_PRESETZ>;
			power-domains = <&cpg>;
			status = "disabled";
		};

		ssi0: ssi@100a8000 {
			compatible = "renesas,r9a08g045-ssi",
				     "renesas,rz-ssi";
			reg = <0 0x100a8000 0 0x400>;
			interrupts = <GIC_SPI 240 IRQ_TYPE_LEVEL_HIGH>,
				     <GIC_SPI 241 IRQ_TYPE_EDGE_RISING>,
				     <GIC_SPI 242 IRQ_TYPE_EDGE_RISING>;
			interrupt-names = "int_req", "dma_rx", "dma_tx";
			clocks = <&cpg CPG_MOD R9A08G045_SSI0_PCLK2>,
				 <&cpg CPG_MOD R9A08G045_SSI0_PCLK_SFR>,
				 <&audio_clk1>, <&audio_clk2>;
			clock-names = "ssi", "ssi_sfr", "audio_clk1", "audio_clk2";
			resets = <&cpg R9A08G045_SSI0_RST_M2_REG>;
			dmas = <&dmac 0x2665>, <&dmac 0x2666>;
			dma-names = "tx", "rx";
			power-domains = <&cpg>;
			#sound-dai-cells = <0>;
			status = "disabled";
		};

		ssi1: ssi@100a8400 {
			compatible = "renesas,r9a08g045-ssi",
				     "renesas,rz-ssi";
			reg = <0 0x100a8400 0 0x400>;
			interrupts = <GIC_SPI 243 IRQ_TYPE_LEVEL_HIGH>,
				     <GIC_SPI 244 IRQ_TYPE_EDGE_RISING>,
				     <GIC_SPI 245 IRQ_TYPE_EDGE_RISING>;
			interrupt-names = "int_req", "dma_rx", "dma_tx";
			clocks = <&cpg CPG_MOD R9A08G045_SSI1_PCLK2>,
				 <&cpg CPG_MOD R9A08G045_SSI1_PCLK_SFR>,
				 <&audio_clk1>, <&audio_clk2>;
			clock-names = "ssi", "ssi_sfr", "audio_clk1", "audio_clk2";
			resets = <&cpg R9A08G045_SSI1_RST_M2_REG>;
			dmas = <&dmac 0x2669>, <&dmac 0x266a>;
			dma-names = "tx", "rx";
			power-domains = <&cpg>;
			#sound-dai-cells = <0>;
			status = "disabled";
		};

		ssi2: ssi@100a8800 {
			compatible = "renesas,r9a08g045-ssi",
				     "renesas,rz-ssi";
			reg = <0 0x100a8800 0 0x400>;
			interrupts = <GIC_SPI 246 IRQ_TYPE_LEVEL_HIGH>,
				     <GIC_SPI 247 IRQ_TYPE_EDGE_RISING>,
				     <GIC_SPI 248 IRQ_TYPE_EDGE_RISING>;
			interrupt-names = "int_req", "dma_rx", "dma_tx";
			clocks = <&cpg CPG_MOD R9A08G045_SSI2_PCLK2>,
				 <&cpg CPG_MOD R9A08G045_SSI2_PCLK_SFR>,
				 <&audio_clk1>, <&audio_clk2>;
			clock-names = "ssi", "ssi_sfr", "audio_clk1", "audio_clk2";
			resets = <&cpg R9A08G045_SSI2_RST_M2_REG>;
			dmas = <&dmac 0x266d>, <&dmac 0x266e>;
			dma-names = "tx", "rx";
			power-domains = <&cpg>;
			#sound-dai-cells = <0>;
			status = "disabled";
		};

		ssi3: ssi@100a8c00 {
			compatible = "renesas,r9a08g045-ssi",
				     "renesas,rz-ssi";
			reg = <0 0x100a8c00 0 0x400>;
			interrupts = <GIC_SPI 249 IRQ_TYPE_LEVEL_HIGH>,
				     <GIC_SPI 250 IRQ_TYPE_EDGE_RISING>,
				     <GIC_SPI 251 IRQ_TYPE_EDGE_RISING>;
			interrupt-names = "int_req", "dma_rx", "dma_tx";
			clocks = <&cpg CPG_MOD R9A08G045_SSI3_PCLK2>,
				 <&cpg CPG_MOD R9A08G045_SSI3_PCLK_SFR>,
				 <&audio_clk1>, <&audio_clk2>;
			clock-names = "ssi", "ssi_sfr", "audio_clk1", "audio_clk2";
			resets = <&cpg R9A08G045_SSI3_RST_M2_REG>;
			dmas = <&dmac 0x2671>, <&dmac 0x2672>;
			dma-names = "tx", "rx";
			power-domains = <&cpg>;
			#sound-dai-cells = <0>;
			status = "disabled";
		};

		spdif: spdif@100a9000 {
			compatible = "renesas,r9a08g045-spdif",
				     "renesas,rz-spdif";
			reg = <0 0x100a9000 0 0x400>;
			interrupts = <GIC_SPI 387 IRQ_TYPE_LEVEL_HIGH>;
			interrupt-names = "intreq_spdif_n";
			clocks = <&cpg CPG_MOD R9A08G045_SPDIF_PCLK>,
				 <&audio_clk1>, <&audio_clk2>;
			clock-names = "spdif-tx-rx", "audio_clk1", "audio_clk2";
			resets = <&cpg R9A08G045_SPDIF_RST>;
			dmas = <&dmac 0x1e79>, <&dmac 0x1e7a>;
			dma-names = "tx", "rx";
			power-domains = <&cpg>;
			#sound-dai-cells = <0>;
			rz,spdif-mode = <1>;
			status = "disabled";
		};

		phyrst: usbphy-ctrl@11e00000 {
			compatible = "renesas,r9a08g045-usbphy-ctrl",
				     "renesas,rzg2l-usbphy-ctrl";
			reg = <0 0x11e00000 0 0x10000>;
			clocks = <&cpg CPG_MOD R9A08G045_USB_PCLK>;
			resets = <&cpg R9A08G045_USB_PRESETN>;
			power-domains = <&cpg>;
			#reset-cells = <1>;
			status = "disabled";
		};

		ohci0: usb@11e10000 {
			compatible = "generic-ohci";
			reg = <0 0x11e10000 0 0x100>;
			interrupts = <GIC_SPI 75 IRQ_TYPE_LEVEL_HIGH>;
			clocks = <&cpg CPG_MOD R9A08G045_USB_PCLK>,
				 <&cpg CPG_MOD R9A08G045_USB_U2H0_HCLK>;
			resets = <&phyrst 0>,
				 <&cpg R9A08G045_USB_U2H0_HRESETN>;
			phys = <&usb2_phy0 1>;
			phy-names = "usb";
			power-domains = <&cpg>;
			status = "disabled";
		};

		ohci1: usb@11e30000 {
			compatible = "generic-ohci";
			reg = <0 0x11e30000 0 0x100>;
			interrupts = <GIC_SPI 80 IRQ_TYPE_LEVEL_HIGH>;
			clocks = <&cpg CPG_MOD R9A08G045_USB_PCLK>,
				 <&cpg CPG_MOD R9A08G045_USB_U2H1_HCLK>;
			resets = <&phyrst 1>,
				 <&cpg R9A08G045_USB_U2H1_HRESETN>;
			phys = <&usb2_phy1 1>;
			phy-names = "usb";
			power-domains = <&cpg>;
			status = "disabled";
		};

		ehci0: usb@11e10100 {
			compatible = "generic-ehci";
			reg = <0 0x11e10100 0 0x100>;
			interrupts = <GIC_SPI 76 IRQ_TYPE_LEVEL_HIGH>;
			clocks = <&cpg CPG_MOD R9A08G045_USB_PCLK>,
				 <&cpg CPG_MOD R9A08G045_USB_U2H0_HCLK>;
			resets = <&phyrst 0>,
				 <&cpg R9A08G045_USB_U2H0_HRESETN>;
			phys = <&usb2_phy0 2>;
			phy-names = "usb";
			companion = <&ohci0>;
			power-domains = <&cpg>;
			status = "disabled";
		};

		ehci1: usb@11e30100 {
			compatible = "generic-ehci";
			reg = <0 0x11e30100 0 0x100>;
			interrupts = <GIC_SPI 81 IRQ_TYPE_LEVEL_HIGH>;
			clocks = <&cpg CPG_MOD R9A08G045_USB_PCLK>,
				 <&cpg CPG_MOD R9A08G045_USB_U2H1_HCLK>;
			resets = <&phyrst 1>,
				 <&cpg R9A08G045_USB_U2H1_HRESETN>;
			phys = <&usb2_phy1 2>;
			phy-names = "usb";
			companion = <&ohci1>;
			power-domains = <&cpg>;
			status = "disabled";
		};

		usb2_phy0: usb-phy@11e10200 {
			compatible = "renesas,usb2-phy-r9a08g045",
				     "renesas,g3s-usb2-phy";
			reg = <0 0x11e10200 0 0x700>;
			interrupts = <GIC_SPI 78 IRQ_TYPE_LEVEL_HIGH>;
			clocks = <&cpg CPG_MOD R9A08G045_USB_PCLK>,
				 <&cpg CPG_MOD R9A08G045_USB_U2H0_HCLK>;
			resets = <&phyrst 0>;
			#phy-cells = <1>;
			power-domains = <&cpg>;
			status = "disabled";
		};

		usb2_phy1: usb-phy@11e30200 {
			compatible = "renesas,usb2-phy-r9a08g045",
				     "renesas,g3s-usb2-phy";
			reg = <0 0x11e30200 0 0x700>;
			interrupts = <GIC_SPI 83 IRQ_TYPE_LEVEL_HIGH>;
			clocks = <&cpg CPG_MOD R9A08G045_USB_PCLK>,
				 <&cpg CPG_MOD R9A08G045_USB_U2H1_HCLK>;
			resets = <&phyrst 1>;
			#phy-cells = <1>;
			power-domains = <&cpg>;
			status = "disabled";
		};

		hsusb: usb@11e20000 {
			compatible = "renesas,usbhs-r9a08g045",
				     "renesas,rzg2l-usbhs";
			reg = <0 0x11e20000 0 0x10000>;
			interrupts = <GIC_SPI 85 IRQ_TYPE_EDGE_RISING>,
				     <GIC_SPI 86 IRQ_TYPE_LEVEL_HIGH>,
				     <GIC_SPI 87 IRQ_TYPE_LEVEL_HIGH>,
				     <GIC_SPI 84 IRQ_TYPE_LEVEL_HIGH>;
			clocks = <&cpg CPG_MOD R9A08G045_USB_PCLK>,
				 <&cpg CPG_MOD R9A08G045_USB_U2P_EXR_CPUCLK>;
			resets = <&phyrst 0>,
				 <&cpg R9A08G045_USB_U2P_EXL_SYSRST>;
			renesas,buswait = <7>;
			phys = <&usb2_phy0 3>;
			phy-names = "usb";
			power-domains = <&cpg>;
			status = "disabled";
		};

		mtu3: timer@10001200 {
			compatible = "renesas,r9a08g045-mtu3",
				     "renesas,rz-mtu3";
			reg = <0 0x10001200 0 0xB00>;
			interrupts =
				<GIC_SPI 132 IRQ_TYPE_LEVEL_HIGH>,
				<GIC_SPI 133 IRQ_TYPE_LEVEL_HIGH>,
				<GIC_SPI 134 IRQ_TYPE_LEVEL_HIGH>,
				<GIC_SPI 135 IRQ_TYPE_LEVEL_HIGH>,
				<GIC_SPI 136 IRQ_TYPE_LEVEL_HIGH>,
				<GIC_SPI 137 IRQ_TYPE_LEVEL_HIGH>,
				<GIC_SPI 145 IRQ_TYPE_LEVEL_HIGH>,
				<GIC_SPI 146 IRQ_TYPE_LEVEL_HIGH>,
				<GIC_SPI 147 IRQ_TYPE_LEVEL_HIGH>,
				<GIC_SPI 148 IRQ_TYPE_LEVEL_HIGH>,
				<GIC_SPI 149 IRQ_TYPE_LEVEL_HIGH>,
				<GIC_SPI 150 IRQ_TYPE_LEVEL_HIGH>,
				<GIC_SPI 158 IRQ_TYPE_LEVEL_HIGH>,
				<GIC_SPI 159 IRQ_TYPE_LEVEL_HIGH>,
				<GIC_SPI 160 IRQ_TYPE_LEVEL_HIGH>,
				<GIC_SPI 161 IRQ_TYPE_LEVEL_HIGH>,
				<GIC_SPI 162 IRQ_TYPE_LEVEL_HIGH>,
				<GIC_SPI 163 IRQ_TYPE_LEVEL_HIGH>,
				<GIC_SPI 171 IRQ_TYPE_LEVEL_HIGH>,
				<GIC_SPI 172 IRQ_TYPE_LEVEL_HIGH>,
				<GIC_SPI 173 IRQ_TYPE_LEVEL_HIGH>,
				<GIC_SPI 174 IRQ_TYPE_LEVEL_HIGH>,
				<GIC_SPI 175 IRQ_TYPE_LEVEL_HIGH>,
				<GIC_SPI 176 IRQ_TYPE_LEVEL_HIGH>,
				<GIC_SPI 184 IRQ_TYPE_LEVEL_HIGH>,
				<GIC_SPI 185 IRQ_TYPE_LEVEL_HIGH>,
				<GIC_SPI 186 IRQ_TYPE_LEVEL_HIGH>,
				<GIC_SPI 187 IRQ_TYPE_LEVEL_HIGH>,
				<GIC_SPI 188 IRQ_TYPE_LEVEL_HIGH>,
				<GIC_SPI 189 IRQ_TYPE_LEVEL_HIGH>,
				<GIC_SPI 197 IRQ_TYPE_LEVEL_HIGH>,
				<GIC_SPI 198 IRQ_TYPE_LEVEL_HIGH>,
				<GIC_SPI 199 IRQ_TYPE_LEVEL_HIGH>,
				<GIC_SPI 200 IRQ_TYPE_LEVEL_HIGH>,
				<GIC_SPI 201 IRQ_TYPE_LEVEL_HIGH>,
				<GIC_SPI 202 IRQ_TYPE_LEVEL_HIGH>,
				<GIC_SPI 210 IRQ_TYPE_LEVEL_HIGH>,
				<GIC_SPI 211 IRQ_TYPE_LEVEL_HIGH>,
				<GIC_SPI 212 IRQ_TYPE_LEVEL_HIGH>,
				<GIC_SPI 213 IRQ_TYPE_LEVEL_HIGH>,
				<GIC_SPI 214 IRQ_TYPE_LEVEL_HIGH>,
				<GIC_SPI 215 IRQ_TYPE_LEVEL_HIGH>,
				<GIC_SPI 223 IRQ_TYPE_LEVEL_HIGH>,
				<GIC_SPI 224 IRQ_TYPE_LEVEL_HIGH>;
			interrupt-names = "tgia0", "tgib0", "tgic0", "tgid0",
					  "tciv0", "tgie0", "tgif0",
					  "tgia1", "tgib1", "tciv1", "tciu1",
					  "tgia2", "tgib2", "tciv2", "tciu2",
					  "tgia3", "tgib3", "tgic3", "tgid3",
					  "tciv3",
					  "tgia4", "tgib4", "tgic4", "tgid4",
					  "tciv4",
					  "tgiu5", "tgiv5", "tgiw5",
					  "tgia6", "tgib6", "tgic6", "tgid6",
					  "tciv6",
					  "tgia7", "tgib7", "tgic7", "tgid7",
					  "tciv7",
					  "tgia8", "tgib8", "tgic8", "tgid8",
					  "tciv8", "tciu8";
			clocks = <&cpg CPG_MOD R9A08G045_MTU_X_MCK_MTU3>;
			clock-names = "fck";
			power-domains = <&cpg>;
			#pwm-cells = <2>;
			resets = <&cpg R9A08G045_MTU_X_PRESET_MTU3>;
			status = "disabled";
		};

		gpt0: gpt@10048000 {
			compatible = "renesas,gpt-r9a08g045",
				     "renesas,gpt-r9a07g044";
			reg = <0 0x10048000 0 0xa4>;
			#pwm-cells = <2>;
			interrupts = <GIC_SPI 128 IRQ_TYPE_EDGE_RISING>,
				<GIC_SPI 129 IRQ_TYPE_EDGE_RISING>,
				<GIC_SPI 130 IRQ_TYPE_EDGE_RISING>,
				<GIC_SPI 131 IRQ_TYPE_EDGE_RISING>,
				<GIC_SPI 132 IRQ_TYPE_EDGE_RISING>,
				<GIC_SPI 133 IRQ_TYPE_EDGE_RISING>,
				<GIC_SPI 134 IRQ_TYPE_EDGE_RISING>,
				<GIC_SPI 135 IRQ_TYPE_EDGE_RISING>,
				<GIC_SPI 136 IRQ_TYPE_EDGE_RISING>,
				<GIC_SPI 137 IRQ_TYPE_EDGE_RISING>,
				<GIC_SPI 138 IRQ_TYPE_EDGE_RISING>,
				<GIC_SPI 139 IRQ_TYPE_EDGE_RISING>,
				<GIC_SPI 140 IRQ_TYPE_EDGE_RISING>;
			interrupt-names = "gtcia", "gtcib", "gtcic", "gtcid",
				"gtcie", "gtcif", "gtciada", "gtciadb",
				"gtciv", "gtciu", "gtcih", "gtcil",
				"gtdei";
			clocks = <&cpg CPG_MOD R9A08G045_GPT_PCLK>;
			power-domains = <&cpg>;
			resets =  <&cpg R9A08G045_GPT_RST_C>;
			status = "disabled";
		};

		gpt1: gpt@10048100 {
			compatible = "renesas,gpt-r9a08g045",
				     "renesas,gpt-r9a07g044";
			reg = <0 0x10048100 0 0xa4>;
			#pwm-cells = <2>;
			interrupts = <GIC_SPI 141 IRQ_TYPE_EDGE_RISING>,
				<GIC_SPI 142 IRQ_TYPE_EDGE_RISING>,
				<GIC_SPI 143 IRQ_TYPE_EDGE_RISING>,
				<GIC_SPI 144 IRQ_TYPE_EDGE_RISING>,
				<GIC_SPI 145 IRQ_TYPE_EDGE_RISING>,
				<GIC_SPI 146 IRQ_TYPE_EDGE_RISING>,
				<GIC_SPI 147 IRQ_TYPE_EDGE_RISING>,
				<GIC_SPI 148 IRQ_TYPE_EDGE_RISING>,
				<GIC_SPI 149 IRQ_TYPE_EDGE_RISING>,
				<GIC_SPI 150 IRQ_TYPE_EDGE_RISING>,
				<GIC_SPI 151 IRQ_TYPE_EDGE_RISING>,
				<GIC_SPI 152 IRQ_TYPE_EDGE_RISING>,
				<GIC_SPI 153 IRQ_TYPE_EDGE_RISING>;
			interrupt-names = "gtcia", "gtcib", "gtcic", "gtcid",
				"gtcie", "gtcif", "gtciada", "gtciadb",
				"gtciv", "gtciu", "gtcih", "gtcil",
				"gtdei";
			clocks = <&cpg CPG_MOD R9A08G045_GPT_PCLK>;
			power-domains = <&cpg>;
			resets =  <&cpg R9A08G045_GPT_RST_C>;
			status = "disabled";
		};

		gpt2: gpt@10048200 {
			compatible = "renesas,gpt-r9a08g045",
				     "renesas,gpt-r9a07g044";
			reg = <0 0x10048200 0 0xa4>;
			#pwm-cells = <2>;
			interrupts = <GIC_SPI 154 IRQ_TYPE_EDGE_RISING>,
				<GIC_SPI 155 IRQ_TYPE_EDGE_RISING>,
				<GIC_SPI 156 IRQ_TYPE_EDGE_RISING>,
				<GIC_SPI 157 IRQ_TYPE_EDGE_RISING>,
				<GIC_SPI 158 IRQ_TYPE_EDGE_RISING>,
				<GIC_SPI 159 IRQ_TYPE_EDGE_RISING>,
				<GIC_SPI 160 IRQ_TYPE_EDGE_RISING>,
				<GIC_SPI 161 IRQ_TYPE_EDGE_RISING>,
				<GIC_SPI 162 IRQ_TYPE_EDGE_RISING>,
				<GIC_SPI 163 IRQ_TYPE_EDGE_RISING>,
				<GIC_SPI 164 IRQ_TYPE_EDGE_RISING>,
				<GIC_SPI 165 IRQ_TYPE_EDGE_RISING>,
				<GIC_SPI 166 IRQ_TYPE_EDGE_RISING>;
			interrupt-names = "gtcia", "gtcib", "gtcic", "gtcid",
				"gtcie", "gtcif", "gtciada", "gtciadb",
				"gtciv", "gtciu", "gtcih", "gtcil",
				"gtdei";
			clocks = <&cpg CPG_MOD R9A08G045_GPT_PCLK>;
			power-domains = <&cpg>;
			resets =  <&cpg R9A08G045_GPT_RST_C>;
			status = "disabled";
		};

		gpt3: gpt@10048300 {
			compatible = "renesas,gpt-r9a08g045",
				     "renesas,gpt-r9a07g044";
			reg = <0 0x10048300 0 0xa4>;
			#pwm-cells = <2>;
			interrupts = <GIC_SPI 167 IRQ_TYPE_EDGE_RISING>,
				<GIC_SPI 168 IRQ_TYPE_EDGE_RISING>,
				<GIC_SPI 169 IRQ_TYPE_EDGE_RISING>,
				<GIC_SPI 170 IRQ_TYPE_EDGE_RISING>,
				<GIC_SPI 171 IRQ_TYPE_EDGE_RISING>,
				<GIC_SPI 172 IRQ_TYPE_EDGE_RISING>,
				<GIC_SPI 173 IRQ_TYPE_EDGE_RISING>,
				<GIC_SPI 174 IRQ_TYPE_EDGE_RISING>,
				<GIC_SPI 175 IRQ_TYPE_EDGE_RISING>,
				<GIC_SPI 176 IRQ_TYPE_EDGE_RISING>,
				<GIC_SPI 177 IRQ_TYPE_EDGE_RISING>,
				<GIC_SPI 178 IRQ_TYPE_EDGE_RISING>,
				<GIC_SPI 179 IRQ_TYPE_EDGE_RISING>;
			interrupt-names = "gtcia", "gtcib", "gtcic", "gtcid",
				"gtcie", "gtcif", "gtciada", "gtciadb",
				"gtciv", "gtciu", "gtcih", "gtcil",
				"gtdei";
			clocks = <&cpg CPG_MOD R9A08G045_GPT_PCLK>;
			power-domains = <&cpg>;
			resets =  <&cpg R9A08G045_GPT_RST_C>;
			status = "disabled";
		};

		gpt4: gpt@10048400 {
			compatible = "renesas,gpt-r9a08g045",
				     "renesas,gpt-r9a07g044";
			reg = <0 0x10048400 0 0xa4>;
			#pwm-cells = <2>;
			interrupts = <GIC_SPI 180 IRQ_TYPE_EDGE_RISING>,
				<GIC_SPI 181 IRQ_TYPE_EDGE_RISING>,
				<GIC_SPI 182 IRQ_TYPE_EDGE_RISING>,
				<GIC_SPI 183 IRQ_TYPE_EDGE_RISING>,
				<GIC_SPI 184 IRQ_TYPE_EDGE_RISING>,
				<GIC_SPI 185 IRQ_TYPE_EDGE_RISING>,
				<GIC_SPI 186 IRQ_TYPE_EDGE_RISING>,
				<GIC_SPI 187 IRQ_TYPE_EDGE_RISING>,
				<GIC_SPI 188 IRQ_TYPE_EDGE_RISING>,
				<GIC_SPI 189 IRQ_TYPE_EDGE_RISING>,
				<GIC_SPI 190 IRQ_TYPE_EDGE_RISING>,
				<GIC_SPI 191 IRQ_TYPE_EDGE_RISING>,
				<GIC_SPI 192 IRQ_TYPE_EDGE_RISING>;
			interrupt-names = "gtcia", "gtcib", "gtcic", "gtcid",
				"gtcie", "gtcif", "gtciada", "gtciadb",
				"gtciv", "gtciu", "gtcih", "gtcil",
				"gtdei";
			clocks = <&cpg CPG_MOD R9A08G045_GPT_PCLK>;
			power-domains = <&cpg>;
			resets =  <&cpg R9A08G045_GPT_RST_C>;
			status = "disabled";
		};

		gpt5: gpt@10048500 {
			compatible = "renesas,gpt-r9a08g045",
				     "renesas,gpt-r9a07g044";
			reg = <0 0x10048500 0 0xa4>;
			#pwm-cells = <2>;
			interrupts = <GIC_SPI 193 IRQ_TYPE_EDGE_RISING>,
				<GIC_SPI 194 IRQ_TYPE_EDGE_RISING>,
				<GIC_SPI 195 IRQ_TYPE_EDGE_RISING>,
				<GIC_SPI 196 IRQ_TYPE_EDGE_RISING>,
				<GIC_SPI 197 IRQ_TYPE_EDGE_RISING>,
				<GIC_SPI 198 IRQ_TYPE_EDGE_RISING>,
				<GIC_SPI 199 IRQ_TYPE_EDGE_RISING>,
				<GIC_SPI 200 IRQ_TYPE_EDGE_RISING>,
				<GIC_SPI 201 IRQ_TYPE_EDGE_RISING>,
				<GIC_SPI 202 IRQ_TYPE_EDGE_RISING>,
				<GIC_SPI 203 IRQ_TYPE_EDGE_RISING>,
				<GIC_SPI 204 IRQ_TYPE_EDGE_RISING>,
				<GIC_SPI 205 IRQ_TYPE_EDGE_RISING>;
			interrupt-names = "gtcia", "gtcib", "gtcic", "gtcid",
				"gtcie", "gtcif", "gtciada", "gtciadb",
				"gtciv", "gtciu", "gtcih", "gtcil",
				"gtdei";
			clocks = <&cpg CPG_MOD R9A08G045_GPT_PCLK>;
			power-domains = <&cpg>;
			resets =  <&cpg R9A08G045_GPT_RST_C>;
			status = "disabled";
		};

		gpt6: gpt@10048600 {
			compatible = "renesas,gpt-r9a08g045",
				     "renesas,gpt-r9a07g044";
			reg = <0 0x10048600 0 0xa4>;
			#pwm-cells = <2>;
			interrupts = <GIC_SPI 206 IRQ_TYPE_EDGE_RISING>,
				<GIC_SPI 207 IRQ_TYPE_EDGE_RISING>,
				<GIC_SPI 208 IRQ_TYPE_EDGE_RISING>,
				<GIC_SPI 209 IRQ_TYPE_EDGE_RISING>,
				<GIC_SPI 210 IRQ_TYPE_EDGE_RISING>,
				<GIC_SPI 211 IRQ_TYPE_EDGE_RISING>,
				<GIC_SPI 212 IRQ_TYPE_EDGE_RISING>,
				<GIC_SPI 213 IRQ_TYPE_EDGE_RISING>,
				<GIC_SPI 214 IRQ_TYPE_EDGE_RISING>,
				<GIC_SPI 215 IRQ_TYPE_EDGE_RISING>,
				<GIC_SPI 216 IRQ_TYPE_EDGE_RISING>,
				<GIC_SPI 217 IRQ_TYPE_EDGE_RISING>,
				<GIC_SPI 218 IRQ_TYPE_EDGE_RISING>;
			interrupt-names = "gtcia", "gtcib", "gtcic", "gtcid",
				"gtcie", "gtcif", "gtciada", "gtciadb",
				"gtciv", "gtciu", "gtcih", "gtcil",
				"gtdei";
			clocks = <&cpg CPG_MOD R9A08G045_GPT_PCLK>;
			power-domains = <&cpg>;
			resets =  <&cpg R9A08G045_GPT_RST_C>;
			status = "disabled";
		};

		gpt7: gpt@10048700 {
			compatible = "renesas,gpt-r9a08g045",
				     "renesas,gpt-r9a07g044";
			reg = <0 0x10048700 0 0xa4>;
			#pwm-cells = <2>;
			interrupts = <GIC_SPI 219 IRQ_TYPE_EDGE_RISING>,
				<GIC_SPI 220 IRQ_TYPE_EDGE_RISING>,
				<GIC_SPI 221 IRQ_TYPE_EDGE_RISING>,
				<GIC_SPI 222 IRQ_TYPE_EDGE_RISING>,
				<GIC_SPI 223 IRQ_TYPE_EDGE_RISING>,
				<GIC_SPI 224 IRQ_TYPE_EDGE_RISING>,
				<GIC_SPI 225 IRQ_TYPE_EDGE_RISING>,
				<GIC_SPI 226 IRQ_TYPE_EDGE_RISING>,
				<GIC_SPI 227 IRQ_TYPE_EDGE_RISING>,
				<GIC_SPI 228 IRQ_TYPE_EDGE_RISING>,
				<GIC_SPI 229 IRQ_TYPE_EDGE_RISING>,
				<GIC_SPI 230 IRQ_TYPE_EDGE_RISING>,
				<GIC_SPI 231 IRQ_TYPE_EDGE_RISING>;
			interrupt-names = "gtcia", "gtcib", "gtcic", "gtcid",
				"gtcie", "gtcif", "gtciada", "gtciadb",
				"gtciv", "gtciu", "gtcih", "gtcil",
				"gtdei";
			clocks = <&cpg CPG_MOD R9A08G045_GPT_PCLK>;
			power-domains = <&cpg>;
			resets =  <&cpg R9A08G045_GPT_RST_C>;
			status = "disabled";
		};

		poega: poega@10048800 {
			compatible = "renesas,poeg-r9a08g045",
				     "renesas,poeg-r9a07g044";
			reg = <0 0x10048800 0 0x04>;
			interrupts = <GIC_SPI 236 IRQ_TYPE_LEVEL_HIGH>;
			clocks = <&cpg CPG_MOD R9A08G045_POEG_A_CLKP>;
			power-domains = <&cpg>;
			resets =  <&cpg R9A08G045_POEG_A_RST>;
			status = "disabled";
		};

		poegb: poegb@10048C00 {
			compatible = "renesas,poeg-r9a08g045",
				     "renesas,poeg-r9a07g044";
			reg = <0 0x10048C00 0 0x04>;
			interrupts = <GIC_SPI 237 IRQ_TYPE_LEVEL_HIGH>;
			clocks = <&cpg CPG_MOD R9A08G045_POEG_B_CLKP>;
			power-domains = <&cpg>;
			resets =  <&cpg R9A08G045_POEG_B_RST>;
			status = "disabled";
		};

		poegc: poegc@10049000 {
			compatible = "renesas,poeg-r9a08g045",
				     "renesas,poeg-r9a07g044";
			reg = <0 0x10049000 0 0x04>;
			interrupts = <GIC_SPI 238 IRQ_TYPE_LEVEL_HIGH>;
			clocks = <&cpg CPG_MOD R9A08G045_POEG_C_CLKP>;
			power-domains = <&cpg>;
			resets =  <&cpg R9A08G045_POEG_C_RST>;
			status = "disabled";
		};

		poegd: poegd@10049400 {
			compatible = "renesas,poeg-r9a08g045",
				     "renesas,poeg-r9a07g044";
			reg = <0 0x10049400 0 0x04>;
			interrupts = <GIC_SPI 239 IRQ_TYPE_LEVEL_HIGH>;
			clocks = <&cpg CPG_MOD R9A08G045_POEG_D_CLKP>;
			power-domains = <&cpg>;
			resets =  <&cpg R9A08G045_POEG_D_RST>;
			status = "disabled";
		};

		poe3: poe3@10049800 {
			compatible = "renesas,r9a08g045-poe3",
				     "renesas,rz-poe3";
			reg = <0 0x10049800 0 0x18>;
			interrupts = <GIC_SPI 232 IRQ_TYPE_LEVEL_HIGH>,
				     <GIC_SPI 233 IRQ_TYPE_LEVEL_HIGH>,
				     <GIC_SPI 234 IRQ_TYPE_LEVEL_HIGH>,
				     <GIC_SPI 235 IRQ_TYPE_LEVEL_HIGH>;
			interrupt-names = "oei1", "oei2", "oei3", "oei4";
			clocks = <&cpg CPG_MOD R9A08G045_POE3_CLKM_POE>;
			clock-names = "fck";
			resets = <&cpg R9A08G045_POE3_RST_M_REG>;
			power-domains = <&cpg>;
			status = "disabled";
		};

		xspi: spi@10060000 {
			compatible = "renesas,g3s-xspi-if";
			reg = <0 0x10060000 0 0x10000>,
			      <0 0x20000000 0 0x10000000>;
			reg-names = "regs", "dirmap";
			clocks = <&cpg CPG_MOD R9A08G045_SPI_CLK>,
				 <&cpg CPG_MOD R9A08G045_SPI_HCLK>,
				 <&cpg CPG_MOD R9A08G045_SPI_ACLK>,
				 <&cpg CPG_MOD R9A08G045_SPI_CLKX2>;
			resets = <&cpg R9A08G045_SPI_HRESETN>,
				 <&cpg R9A08G045_SPI_ARESETN>;
			power-domains = <&cpg>;
			#address-cells = <1>;
			#size-cells = <0>;
			status = "disabled";
		};

		tsu: thermal@10059400 {
			compatible = "renesas,rzg3s-tsu";
			reg = <0 0x10059400 0 0x400>;
			clocks = <&cpg CPG_MOD R9A08G045_TSU_PCLK>;
			resets = <&cpg R9A08G045_TSU_PRESETN>;
			power-domains = <&cpg>;
			adc-handle = <&adc>;
			#thermal-sensor-cells = <1>;
		};
	};

	timer {
		compatible = "arm,armv8-timer";
		interrupts-extended = <&gic GIC_PPI 13 IRQ_TYPE_LEVEL_LOW>,
				      <&gic GIC_PPI 14 IRQ_TYPE_LEVEL_LOW>,
				      <&gic GIC_PPI 11 IRQ_TYPE_LEVEL_LOW>,
				      <&gic GIC_PPI 10 IRQ_TYPE_LEVEL_LOW>;
	};

	thermal-zones {
		cpu-thermal {
			polling-delay-passive = <250>;
			polling-delay = <1000>;
			thermal-sensors = <&tsu 0>;
			sustainable-power = <717>;
			cooling-maps {
				map0 {
					trip = <&target>;
					cooling-device = <&cpu0 0 2>;
					contribution = <1024>;
				};
			};
			trips {
				sensor_crit: sensor-crit {
					temperature = <118000>;
					hysteresis = <1000>;
					type = "critical";
				};
				target: trip-point {
					temperature = <93000>;
					hysteresis = <1000>;
					type = "passive";
				};
			};
		};
	};
};
